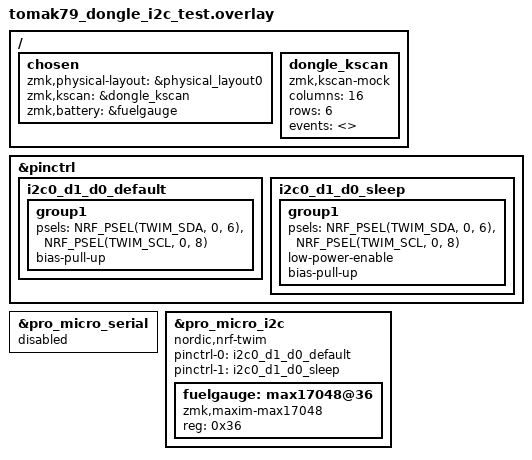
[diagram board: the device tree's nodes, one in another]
#include "tomak79.dtsi"

/ {
    chosen {
        zmk,physical-layout = &physical_layout0;
        zmk,kscan = &dongle_kscan;
        zmk,battery = &fuelgauge;
    };

    dongle_kscan: dongle_kscan {
        compatible = "zmk,kscan-mock";
        status = "okay";
        columns = <16>;
        rows = <6>;
        events = <>;
    };
};

&pinctrl {
    i2c0_d1_d0_default: i2c0_d1_d0_default {
        group1 {
            psels = <NRF_PSEL(TWIM_SDA, 0, 6)>,
                <NRF_PSEL(TWIM_SCL, 0, 8)>;
            bias-pull-up;
        };
    };

    i2c0_d1_d0_sleep: i2c0_d1_d0_sleep {
        group1 {
            psels = <NRF_PSEL(TWIM_SDA, 0, 6)>,
                <NRF_PSEL(TWIM_SCL, 0, 8)>;
            low-power-enable;
            bias-pull-up;
        };
    };
};

&pro_micro_serial {
    status = "disabled";
};

&pro_micro_i2c {
    status = "okay";
    compatible = "nordic,nrf-twim";
    pinctrl-0 = <&i2c0_d1_d0_default>;
    pinctrl-1 = <&i2c0_d1_d0_sleep>;
    pinctrl-names = "default", "sleep";

    fuelgauge: max17048@36 {
        compatible = "zmk,maxim-max17048";
        status = "okay";
        reg = <0x36>;
    };
};
